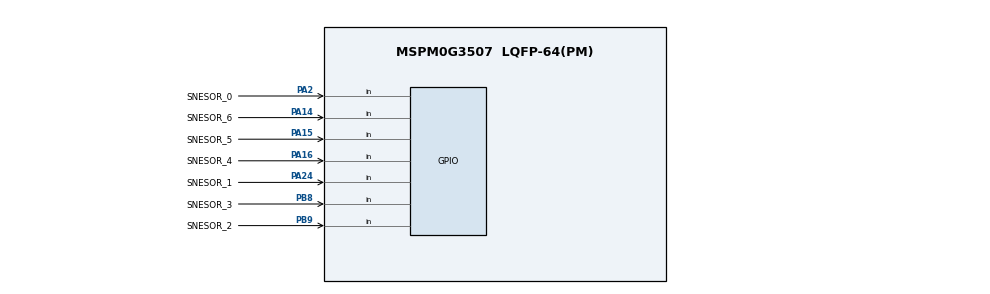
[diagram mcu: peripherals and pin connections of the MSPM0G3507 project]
/**
 * These arguments were used when this file was generated. They will be automatically applied on subsequent loads
 * via the GUI or CLI. Run CLI with '--help' for additional information on how to override these arguments.
 * @cliArgs --device "MSPM0G350X" --part "Default" --package "LQFP-64(PM)" --product "mspm0_sdk@2.10.00.04"
 * @v2CliArgs --device "MSPM0G3507" --package "LQFP-64(PM)" --product "mspm0_sdk@2.10.00.04"
 * @versions {"tool":"1.26.2+4477"}
 */

/**
 * Import the modules used in this configuration.
 */
const GPIO          = scripting.addModule("/ti/driverlib/GPIO", {}, false);
const GPIO1         = GPIO.addInstance();
const PWM           = scripting.addModule("/ti/driverlib/PWM", {}, false);
const PWM1          = PWM.addInstance();
const SYSCTL        = scripting.addModule("/ti/driverlib/SYSCTL");
const ProjectConfig = scripting.addModule("/ti/project_config/ProjectConfig");

/**
 * Write custom configuration values to the imported modules.
 */
GPIO1.$name                              = "SENSOR_GRP";
GPIO1.associatedPins.create(7);
GPIO1.associatedPins[0].direction        = "INPUT";
GPIO1.associatedPins[0].$name            = "SNESOR_0";
GPIO1.associatedPins[0].internalResistor = "PULL_UP";
GPIO1.associatedPins[0].pin.$assign      = "PA2";
GPIO1.associatedPins[1].$name            = "SNESOR_1";
GPIO1.associatedPins[1].direction        = "INPUT";
GPIO1.associatedPins[1].internalResistor = "PULL_UP";
GPIO1.associatedPins[1].pin.$assign      = "PA24";
GPIO1.associatedPins[2].$name            = "SNESOR_2";
GPIO1.associatedPins[2].direction        = "INPUT";
GPIO1.associatedPins[2].internalResistor = "PULL_UP";
GPIO1.associatedPins[2].pin.$assign      = "PB9";
GPIO1.associatedPins[3].$name            = "SNESOR_3";
GPIO1.associatedPins[3].direction        = "INPUT";
GPIO1.associatedPins[3].internalResistor = "PULL_UP";
GPIO1.associatedPins[3].pin.$assign      = "PB8";
GPIO1.associatedPins[4].$name            = "SNESOR_4";
GPIO1.associatedPins[4].direction        = "INPUT";
GPIO1.associatedPins[4].internalResistor = "PULL_UP";
GPIO1.associatedPins[4].pin.$assign      = "PA16";
GPIO1.associatedPins[5].$name            = "SNESOR_5";
GPIO1.associatedPins[5].direction        = "INPUT";
GPIO1.associatedPins[5].internalResistor = "PULL_UP";
GPIO1.associatedPins[5].pin.$assign      = "PA15";
GPIO1.associatedPins[6].$name            = "SNESOR_6";
GPIO1.associatedPins[6].direction        = "INPUT";
GPIO1.associatedPins[6].internalResistor = "PULL_UP";
GPIO1.associatedPins[6].pin.$assign      = "PA14";

const Board = scripting.addModule("/ti/driverlib/Board", {}, false);

PWM1.$name                                    = "PWM_0";
PWM1.pwmMode                                  = "EDGE_ALIGN_UP";
PWM1.timerCount                               = 32000;
PWM1.peripheral.$assign                       = "TIMA0";
PWM1.peripheral.ccp0Pin.$assignAllowConflicts = "PB14";
PWM1.PWM_CHANNEL_0.$name                      = "ti_driverlib_pwm_PWMTimerCC0";
PWM1.PWM_CHANNEL_0.dutyCycle                  = 90;
PWM1.PWM_CHANNEL_1.$name                      = "ti_driverlib_pwm_PWMTimerCC1";
PWM1.PWM_CHANNEL_1.dutyCycle                  = 10;
PWM1.ccp0PinConfig.$name                      = "ti_driverlib_gpio_GPIOPinGeneric0";
PWM1.ccp1PinConfig.$name                      = "ti_driverlib_gpio_GPIOPinGeneric1";

SYSCTL.forceDefaultClkConfig = true;

ProjectConfig.genLibDrivers = true;
ProjectConfig.genLibCMSIS   = true;

/**
 * Pinmux solution for unlocked pins/peripherals. This ensures that minor changes to the automatic solver in a future
 * version of the tool will not impact the pinmux you originally saw.  These lines can be completely deleted in order to
 * re-solve from scratch.
 */
Board.peripheral.$suggestSolution          = "DEBUGSS";
Board.peripheral.swclkPin.$suggestSolution = "PA20";
Board.peripheral.swdioPin.$suggestSolution = "PA19";
PWM1.peripheral.ccp1Pin.$suggestSolution   = "PA1";
SYSCTL.peripheral.$suggestSolution         = "SYSCTL";
